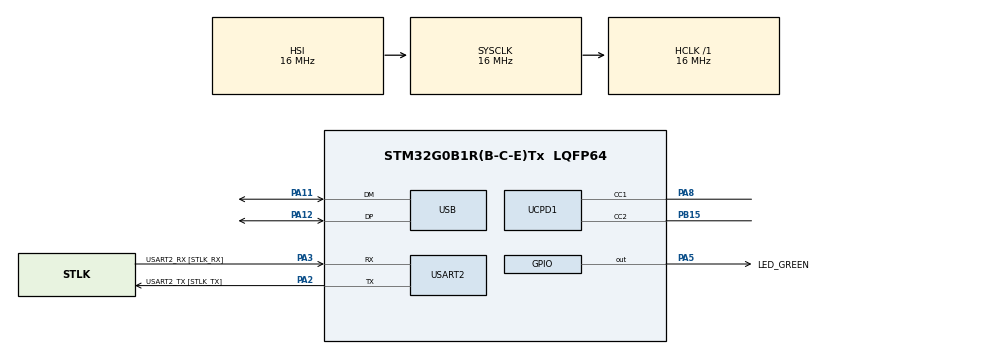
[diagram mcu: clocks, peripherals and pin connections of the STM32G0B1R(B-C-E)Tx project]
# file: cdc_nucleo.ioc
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Mcu.Family=STM32G0
PA11\ [PA9].Mode=Device
USB_DEVICE.CLASS_NAME_FS=CDC
Dma.UCPD1_RX.0.SignalID=NONE
RCC.CortexFreq_Value=16000000
Dma.UCPD1_RX.0.PeriphInc=DMA_PINC_DISABLE
Dma.UCPD1_RX.0.Priority=DMA_PRIORITY_LOW
Dma.UCPD1_TX.1.RequestNumber=1
PA12\ [PA10].Mode=Device
Dma.UCPD1_TX.1.Polarity=HAL_DMAMUX_REQ_GEN_RISING
PA14-BOOT0.Mode=Serial_Wire
PC15-OSC32_OUT\ (PC15).Mode=LSE-External-Oscillator
PF0-OSC_IN\ (PF0).GPIO_Label=MCO
PB15.Signal=UCPD1_CC2
PF0-OSC_IN\ (PF0).Signal=RCC_OSC_IN
ProjectManager.StackSize=0x400
PC14-OSC32_IN\ (PC14).Mode=LSE-External-Oscillator
Dma.UCPD1_TX.1.MemDataAlignment=DMA_MDATAALIGN_BYTE
Dma.UCPD1_TX.1.SyncEnable=DISABLE
RCC.HCLKFreq_Value=16000000
Dma.UCPD1_RX.0.Instance=DMA1_Channel1
PA12\ [PA10].Signal=USB_DP
RCC.AHBFreq_Value=16000000
PA14-BOOT0.Signal=SYS_SWCLK
RCC.HSE_VALUE=8000000
USART2.VirtualMode-Asynchronous=VM_ASYNC
Dma.UCPD1_RX.0.RequestNumber=1
Dma.UCPD1_TX.1.MemInc=DMA_MINC_ENABLE
VP_SYS_VS_DBSignals.Mode=DisableDeadBatterySignals
PA8.Signal=UCPD1_CC1
Dma.UCPD1_RX.0.SyncSignalID=NONE
Mcu.Package=LQFP64
PA2.GPIO_Label=USART2_TX [STLK_TX]
Dma.UCPD1_RX.0.Mode=DMA_NORMAL
Dma.Request1=UCPD1_TX
VP_USBPD_VS_PD3TYPEC_ONLY.Mode=PD3_TypeC
Dma.Request0=UCPD1_RX
RCC.HSI48_VALUE=48000000
PA3.Signal=USART2_RX
PA14-BOOT0.GPIO_Label=TCK
USB_DEVICE.VirtualModeFS=Cdc_FS
PC13.Signal=SYS_WKUP2
RCC.EXTERNAL_CLOCK_VALUE=12288000
PC15-OSC32_OUT\ (PC15).Signal=RCC_OSC32_OUT
Dma.UCPD1_TX.1.SignalID=NONE
Dma.UCPD1_RX.0.MemInc=DMA_MINC_ENABLE
PF0-OSC_IN\ (PF0).Mode=HSE-External-Clock-Source
Dma.UCPD1_TX.1.Direction=DMA_MEMORY_TO_PERIPH
Dma.UCPD1_TX.1.Priority=DMA_PRIORITY_LOW
VP_USBPD_VS_USBPD1.Mode=USBPD_P0
PA13.Signal=SYS_SWDIO
PA3.Mode=Asynchronous
ProjectManager.TargetToolchain=STM32CubeIDE
VP_USB_DEVICE_VS_USB_DEVICE_CDC_FS.Mode=CDC_FS
Dma.UCPD1_TX.1.SyncPolarity=HAL_DMAMUX_SYNC_NO_EVENT
RCC.USBFreq_Value=48000000
Dma.UCPD1_TX.1.PeriphInc=DMA_PINC_DISABLE
PA5.Signal=GPIO_Output
board=NUCLEO-G0B1RE
RCC.VCOOutputFreq_Value=256000000
PB15.Mode=Sink_AllSignals
Dma.UCPD1_TX.1.PeriphDataAlignment=DMA_PDATAALIGN_BYTE
Dma.UCPD1_RX.0.MemDataAlignment=DMA_MDATAALIGN_BYTE
RCC.ADCFreq_Value=16000000
Dma.UCPD1_TX.1.Mode=DMA_NORMAL
Dma.UCPD1_RX.0.SyncEnable=DISABLE
Dma.UCPD1_RX.0.Direction=DMA_PERIPH_TO_MEMORY
Dma.UCPD1_TX.1.EventEnable=DISABLE
PC13.Mode=SYS_WakeUp1
PA13.Mode=Serial_Wire
PA11\ [PA9].Signal=USB_DM
Mcu.Name=STM32G0B1R(B-C-E)Tx
PA13.GPIO_Label=TMS
PA2.Signal=USART2_TX
Dma.UCPD1_RX.0.SyncRequestNumber=1
NVIC.USB_UCPD1_2_IRQn=true\:0\:0\:false\:false\:true\:true\:true
RCC.SYSCLKFreq_VALUE=16000000
PA5.GPIO_Label=LED_GREEN
PC14-OSC32_IN\ (PC14).Signal=RCC_OSC32_IN
Dma.UCPD1_RX.0.SyncPolarity=HAL_DMAMUX_SYNC_NO_EVENT
ProjectManager.HeapSize=0x200
Dma.UCPD1_RX.0.EventEnable=DISABLE
Dma.UCPD1_RX.0.Polarity=HAL_DMAMUX_REQ_GEN_RISING
RCC.HSI_VALUE=16000000
PA5.GPIO_Speed=GPIO_SPEED_FREQ_HIGH
RCC.PLLN=16
NVIC.DMA1_Channel2_3_IRQn=true\:0\:0\:false\:false\:true\:false\:true
PA2.Mode=Asynchronous
PA8.Mode=Sink_AllSignals
Dma.UCPD1_TX.1.SyncSignalID=NONE
Dma.UCPD1_RX.0.PeriphDataAlignment=DMA_PDATAALIGN_BYTE
NVIC.DMA1_Channel1_IRQn=true\:0\:0\:false\:false\:true\:false\:true
Dma.UCPD1_TX.1.Instance=DMA1_Channel2
USB_DEVICE.VirtualMode=Cdc
VP_USBPD_VS_usbpd_tim1.Mode=TIM1
PA3.GPIO_Label=USART2_RX [STLK_RX]
Dma.UCPD1_TX.1.SyncRequestNumber=1

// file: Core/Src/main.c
/* USER CODE BEGIN Header */
/**
  ******************************************************************************
  * @file           : main.c
  * @brief          : Main program body
  ******************************************************************************
  * @attention
  *
  * <h2><center>&copy; Copyright (c) 2021 STMicroelectronics.
  * All rights reserved.</center></h2>
  *
  * This software component is licensed by ST under BSD 3-Clause license,
  * the "License"; You may not use this file except in compliance with the
  * License. You may obtain a copy of the License at:
  *                        opensource.org/licenses/BSD-3-Clause
  *
  ******************************************************************************
  */
/* USER CODE END Header */
#include "main.h"
#include "usbpd.h"
#include "usb_device.h"

UART_HandleTypeDef huart2;

void SystemClock_Config(void);
static void MX_GPIO_Init(void);
static void MX_DMA_Init(void);
static void MX_USART2_UART_Init(void);
static void MX_UCPD1_Init(void);

int main(void)
{

  /* MCU Configuration--------------------------------------------------------*/

  /* Reset of all peripherals, Initializes the Flash interface and the Systick. */
  HAL_Init();

  /* Configure the system clock */
  SystemClock_Config();

  /* Initialize all configured peripherals */
  MX_GPIO_Init();
  MX_DMA_Init();
  MX_USART2_UART_Init();
  MX_USB_Device_Init();
  MX_UCPD1_Init();
  /* USER CODE BEGIN 2 */
  USBPD_HW_IF_GlobalHwInit(); //added
  /* USER CODE END 2 */

  /* USBPD initialisation ---------------------------------*/

//added
  if (USBPD_OK != USBPD_DPM_InitCore())
  {
    Error_Handler();
  }

  MX_USB_Device_Init();

  MX_USBPD_Init();

  //added

  /* Infinite loop */
  while (1)
  {
	  CDC_Transmit_FS("erdem", 5);
  }
}

void SystemClock_Config(void)
{
  RCC_OscInitTypeDef RCC_OscInitStruct = {0};
  RCC_ClkInitTypeDef RCC_ClkInitStruct = {0};
  RCC_PeriphCLKInitTypeDef PeriphClkInit = {0};

  /** Configure the main internal regulator output voltage
  */
  HAL_PWREx_ControlVoltageScaling(PWR_REGULATOR_VOLTAGE_SCALE1);
  /** Initializes the RCC Oscillators according to the specified parameters
  * in the RCC_OscInitTypeDef structure.
  */
  RCC_OscInitStruct.OscillatorType = RCC_OSCILLATORTYPE_HSI|RCC_OSCILLATORTYPE_HSI48;
  RCC_OscInitStruct.HSIState = RCC_HSI_ON;
  RCC_OscInitStruct.HSI48State = RCC_HSI48_ON;
  RCC_OscInitStruct.HSIDiv = RCC_HSI_DIV1;
  RCC_OscInitStruct.HSICalibrationValue = RCC_HSICALIBRATION_DEFAULT;
  RCC_OscInitStruct.PLL.PLLState = RCC_PLL_NONE;
  if (HAL_RCC_OscConfig(&RCC_OscInitStruct) != HAL_OK)
  {
    Error_Handler();
  }
  /** Initializes the CPU, AHB and APB buses clocks
  */
  RCC_ClkInitStruct.ClockType = RCC_CLOCKTYPE_HCLK|RCC_CLOCKTYPE_SYSCLK
                              |RCC_CLOCKTYPE_PCLK1;
  RCC_ClkInitStruct.SYSCLKSource = RCC_SYSCLKSOURCE_HSI;
  RCC_ClkInitStruct.AHBCLKDivider = RCC_SYSCLK_DIV1;
  RCC_ClkInitStruct.APB1CLKDivider = RCC_HCLK_DIV1;

  if (HAL_RCC_ClockConfig(&RCC_ClkInitStruct, FLASH_LATENCY_0) != HAL_OK)
  {
    Error_Handler();
  }
  /** Initializes the peripherals clocks
  */
  PeriphClkInit.PeriphClockSelection = RCC_PERIPHCLK_USART2|RCC_PERIPHCLK_USB;
  PeriphClkInit.Usart2ClockSelection = RCC_USART2CLKSOURCE_PCLK1;
  PeriphClkInit.UsbClockSelection = RCC_USBCLKSOURCE_HSI48;
  if (HAL_RCCEx_PeriphCLKConfig(&PeriphClkInit) != HAL_OK)
  {
    Error_Handler();
  }
}

static void MX_UCPD1_Init(void)
{

  LL_GPIO_InitTypeDef GPIO_InitStruct = {0};

  /* Peripheral clock enable */
  LL_APB1_GRP1_EnableClock(LL_APB1_GRP1_PERIPH_UCPD1);

  LL_IOP_GRP1_EnableClock(LL_IOP_GRP1_PERIPH_GPIOB);
  LL_IOP_GRP1_EnableClock(LL_IOP_GRP1_PERIPH_GPIOA);
  /**UCPD1 GPIO Configuration
  PB15   ------> UCPD1_CC2
  PA8   ------> UCPD1_CC1
  */
  GPIO_InitStruct.Pin = LL_GPIO_PIN_15;
  GPIO_InitStruct.Mode = LL_GPIO_MODE_ANALOG;
  GPIO_InitStruct.Pull = LL_GPIO_PULL_NO;
  LL_GPIO_Init(GPIOB, &GPIO_InitStruct);

  GPIO_InitStruct.Pin = LL_GPIO_PIN_8;
  GPIO_InitStruct.Mode = LL_GPIO_MODE_ANALOG;
  GPIO_InitStruct.Pull = LL_GPIO_PULL_NO;
  LL_GPIO_Init(GPIOA, &GPIO_InitStruct);

  /* UCPD1 DMA Init */

  /* UCPD1_RX Init */
  LL_DMA_SetPeriphRequest(DMA1, LL_DMA_CHANNEL_1, LL_DMAMUX_REQ_UCPD1_RX);

  LL_DMA_SetDataTransferDirection(DMA1, LL_DMA_CHANNEL_1, LL_DMA_DIRECTION_PERIPH_TO_MEMORY);

  LL_DMA_SetChannelPriorityLevel(DMA1, LL_DMA_CHANNEL_1, LL_DMA_PRIORITY_LOW);

  LL_DMA_SetMode(DMA1, LL_DMA_CHANNEL_1, LL_DMA_MODE_NORMAL);

  LL_DMA_SetPeriphIncMode(DMA1, LL_DMA_CHANNEL_1, LL_DMA_PERIPH_NOINCREMENT);

  LL_DMA_SetMemoryIncMode(DMA1, LL_DMA_CHANNEL_1, LL_DMA_MEMORY_INCREMENT);

  LL_DMA_SetPeriphSize(DMA1, LL_DMA_CHANNEL_1, LL_DMA_PDATAALIGN_BYTE);

  LL_DMA_SetMemorySize(DMA1, LL_DMA_CHANNEL_1, LL_DMA_MDATAALIGN_BYTE);

  /* UCPD1_TX Init */
  LL_DMA_SetPeriphRequest(DMA1, LL_DMA_CHANNEL_2, LL_DMAMUX_REQ_UCPD1_TX);

  LL_DMA_SetDataTransferDirection(DMA1, LL_DMA_CHANNEL_2, LL_DMA_DIRECTION_MEMORY_TO_PERIPH);

  LL_DMA_SetChannelPriorityLevel(DMA1, LL_DMA_CHANNEL_2, LL_DMA_PRIORITY_LOW);

  LL_DMA_SetMode(DMA1, LL_DMA_CHANNEL_2, LL_DMA_MODE_NORMAL);

  LL_DMA_SetPeriphIncMode(DMA1, LL_DMA_CHANNEL_2, LL_DMA_PERIPH_NOINCREMENT);

  LL_DMA_SetMemoryIncMode(DMA1, LL_DMA_CHANNEL_2, LL_DMA_MEMORY_INCREMENT);

  LL_DMA_SetPeriphSize(DMA1, LL_DMA_CHANNEL_2, LL_DMA_PDATAALIGN_BYTE);

  LL_DMA_SetMemorySize(DMA1, LL_DMA_CHANNEL_2, LL_DMA_MDATAALIGN_BYTE);

  /* UCPD1 interrupt Init */
  NVIC_SetPriority(USB_UCPD1_2_IRQn, 0);
  NVIC_EnableIRQ(USB_UCPD1_2_IRQn);

}

static void MX_USART2_UART_Init(void)
{

  huart2.Instance = USART2;
  huart2.Init.BaudRate = 115200;
  huart2.Init.WordLength = UART_WORDLENGTH_8B;
  huart2.Init.StopBits = UART_STOPBITS_1;
  huart2.Init.Parity = UART_PARITY_NONE;
  huart2.Init.Mode = UART_MODE_TX_RX;
  huart2.Init.HwFlowCtl = UART_HWCONTROL_NONE;
  huart2.Init.OverSampling = UART_OVERSAMPLING_16;
  huart2.Init.OneBitSampling = UART_ONE_BIT_SAMPLE_DISABLE;
  huart2.Init.ClockPrescaler = UART_PRESCALER_DIV1;
  huart2.AdvancedInit.AdvFeatureInit = UART_ADVFEATURE_NO_INIT;
  if (HAL_UART_Init(&huart2) != HAL_OK)
  {
    Error_Handler();
  }
  if (HAL_UARTEx_SetTxFifoThreshold(&huart2, UART_TXFIFO_THRESHOLD_1_8) != HAL_OK)
  {
    Error_Handler();
  }
  if (HAL_UARTEx_SetRxFifoThreshold(&huart2, UART_RXFIFO_THRESHOLD_1_8) != HAL_OK)
  {
    Error_Handler();
  }
  if (HAL_UARTEx_DisableFifoMode(&huart2) != HAL_OK)
  {
    Error_Handler();
  }

}

static void MX_DMA_Init(void)
{

  /* DMA controller clock enable */
  __HAL_RCC_DMA1_CLK_ENABLE();

  /* DMA interrupt init */
  /* DMA1_Channel1_IRQn interrupt configuration */
  NVIC_SetPriority(DMA1_Channel1_IRQn, 0);
  NVIC_EnableIRQ(DMA1_Channel1_IRQn);
  /* DMA1_Channel2_3_IRQn interrupt configuration */
  NVIC_SetPriority(DMA1_Channel2_3_IRQn, 0);
  NVIC_EnableIRQ(DMA1_Channel2_3_IRQn);

}

static void MX_GPIO_Init(void)
{
  GPIO_InitTypeDef GPIO_InitStruct = {0};

  /* GPIO Ports Clock Enable */
  __HAL_RCC_GPIOC_CLK_ENABLE();
  __HAL_RCC_GPIOF_CLK_ENABLE();
  __HAL_RCC_GPIOA_CLK_ENABLE();
  __HAL_RCC_GPIOB_CLK_ENABLE();

  /*Configure GPIO pin Output Level */
  HAL_GPIO_WritePin(LED_GREEN_GPIO_Port, LED_GREEN_Pin, GPIO_PIN_RESET);

  /*Configure GPIO pin : LED_GREEN_Pin */
  GPIO_InitStruct.Pin = LED_GREEN_Pin;
  GPIO_InitStruct.Mode = GPIO_MODE_OUTPUT_PP;
  GPIO_InitStruct.Pull = GPIO_NOPULL;
  GPIO_InitStruct.Speed = GPIO_SPEED_FREQ_HIGH;
  HAL_GPIO_Init(LED_GREEN_GPIO_Port, &GPIO_InitStruct);

}

void Error_Handler(void)
{
  __disable_irq();
  while (1)
  {
  }
}

/************************ (C) COPYRIGHT STMicroelectronics *****END OF FILE****/
